# ATUC128D3 device description
Architecture: AVR32_UC3; Family: AVR UC3
Registers are 32-bit, read-write, reset 0x0 unless marked. A register's access mark holds for its fields unless they carry their own. Offsets are from the block's base; [hi:lo] are bit positions; lines under a group give offsets from that group; {n}, {i} and the like mark numbered series; 'fields as' and 'values as' point back to an identical list.

## PWMA — Pulse Width Modulation Controller
Instances: PWMA 0xffff4800
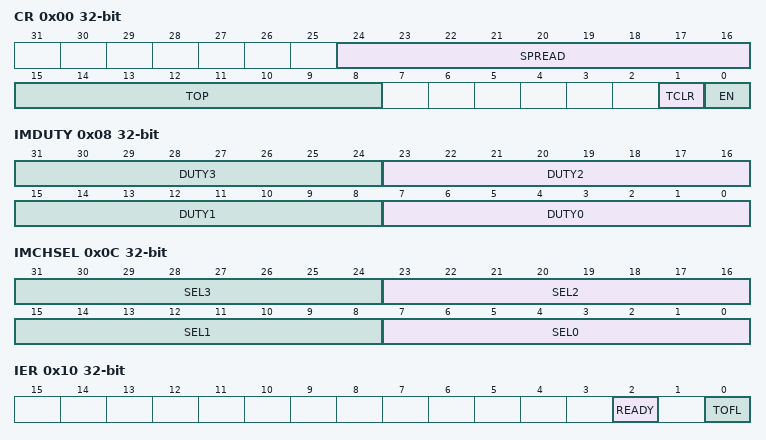
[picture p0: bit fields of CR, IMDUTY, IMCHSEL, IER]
0x00 CR — Control Register
  [24:16] SPREAD — Spread Spectrum Counter Value
  [15:8] TOP — Timebase Counter Top Value
  [1] TCLR — Timebase Clear
  [0] EN — Module enable
0x04 ISDUTY wo — Interlinked Single Value Duty Register
  [11:0] DUTY — Duty Cycle Value
0x08 IMDUTY wo — Interlinked Multiple Value Duty Register
  [8n+7:8n] DUTY{n} (n=0..3) — Duty cycle
0x0C IMCHSEL wo — Interlinked Multiple Value Channel Select
  [8n+7:8n] SEL{n} (n=0..3) — Channel Select {n}
0x10 IER wo — Interrupt Enable Register
  [2] READY — Interface Ready
  [0] TOFL — Timebase Overflow
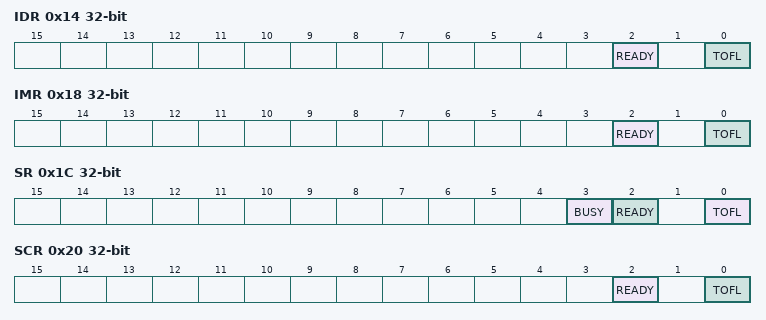
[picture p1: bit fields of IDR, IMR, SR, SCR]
0x14 IDR wo — Interrupt Disable Register
  [2] READY — Interface Ready
  [0] TOFL — Timebase Overflow
0x18 IMR ro — Interrupt Mask Register
  [2] READY — Interface Ready
  [0] TOFL — Timebase Overflow
0x1C SR ro — Status Register
  [3] BUSY — Interface Busy
  [2] READY — Interface Ready
  [0] TOFL — Timebase Overflow
0x20 SCR wo — Status Clear Register
  [2] READY — Interface Ready
  [0] TOFL — Timebase Overflow
0x24 PARAMETER ro reset 0x24
  [7:0] CHANNELS — Channels implemented
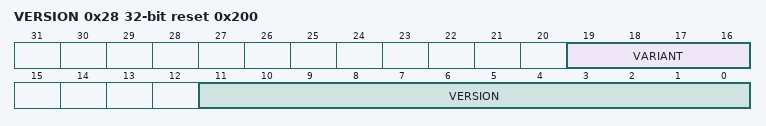
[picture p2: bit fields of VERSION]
0x28 VERSION ro reset 0x200
  [19:16] VARIANT — Variant number
  [11:0] VERSION — Version number
0x2C TVR — Top Value Register
  [11:0] TOP — Timebase Counter Top Value
{0x30+0x10*i} CHGROUP[{i}] (i=0..4) group
  0x00 ISCHSE wo — Interlinked Single Value Channel
    [31:0] SET — Single Value Channel Set
  0x04 CHER — Channel Event Response Register
    [31:0] CHER — Channel Event Response
  0x08 CHEE — Channel Event Enable Register
    [31:0] CHEE — Channel Event Enable
  0x0C CW — Composite Waveform Generator
    [31:0] XOR — Pair Waveform XORed
{0x80+4i} DUTY{i} wo (i=0..3) — Duty Value Register {i}
  [11:0] DUTY — Duty Cycle Value

## TWIM — Two-wire Master Interface
Instances: TWIM 0xffff4000
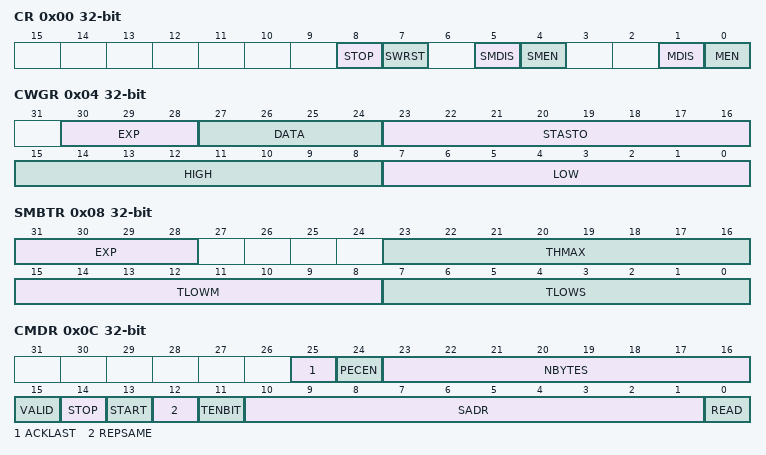
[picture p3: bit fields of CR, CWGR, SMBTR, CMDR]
0x00 CR wo — Control
  [8] STOP — Stop the current transfer
  [7] SWRST — Software Reset
  [5] SMDIS — SMBus Disable
  [4] SMEN — SMBus Enable
  [1] MDIS — Master Disable
  [0] MEN — Master Enable
0x04 CWGR — Clock Waveform Generator
  [30:28] EXP — Clock Prescaler
  [27:24] DATA — Data Setup and Hold Cycles
  [23:16] STASTO — START and STOP Cycles
  [15:8] HIGH — Clock High Cycles
  [7:0] LOW — Clock Low Cycles
0x08 SMBTR — SMBus Timing
  [31:28] EXP — SMBus Timeout Clock prescaler
  [23:16] THMAX — Clock High maximum cycles
  [15:8] TLOWM — Master Clock stretch maximum cycles
  [7:0] TLOWS — Slave Clock stretch maximum cycles
0x0C CMDR — Command
  [25] ACKLAST — ACK Last Master RX Byte
  [24] PECEN — Packet Error Checking Enable
  [23:16] NBYTES — Number of data bytes in transfer
  [15] VALID — CMDR Valid
  [14] STOP — Send STOP condition
  [13] START — Send START condition
  [12] REPSAME — Transfer is to same address as previous address
  [11] TENBIT — Ten Bit Addressing Mode
  [10:1] SADR — Slave Address
  [0] READ — Transfer Direction
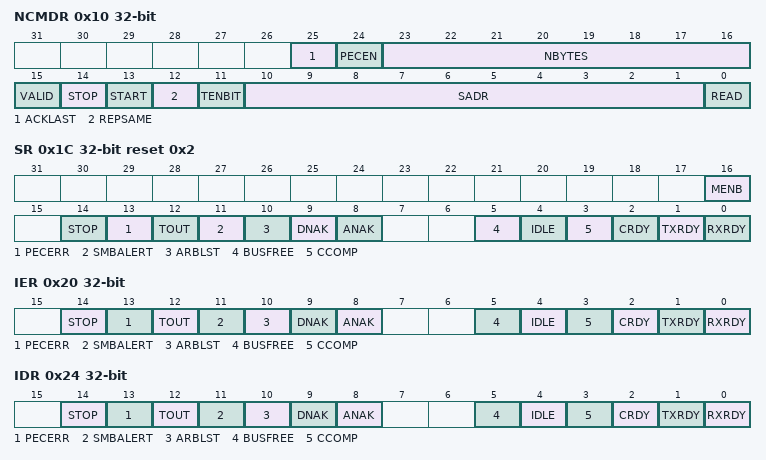
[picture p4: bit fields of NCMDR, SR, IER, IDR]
0x10 NCMDR — Next Command
  fields as CMDR
0x14 RHR ro — Receive Holding
  [7:0] RXDATA — Received Data
0x18 THR wo — Transmit Holding
  [7:0] TXDATA — Data to Transmit
0x1C SR ro reset 0x2 — Status
  [16] MENB — Master Interface Enable
  [14] STOP — Stop Request Accepted
  [13] PECERR — PEC Error
  [12] TOUT — Timeout
  [11] SMBALERT — SMBus Alert
  [10] ARBLST — Arbitration Lost
  [9] DNAK — NAK in Data Phase Received
  [8] ANAK — NAK in Address Phase Received
  [5] BUSFREE — Two-wire Bus is Free
  [4] IDLE — Master Interface is Idle
  [3] CCOMP — Command Complete
  [2] CRDY — Ready for More Commands
  [1] TXRDY — THR Data Ready
  [0] RXRDY — RHR Data Ready
0x20 IER wo — Interrupt Enable Register
  [14] STOP — Stop Request Accepted
  [13] PECERR — PEC Error
  [12] TOUT — Timeout
  [11] SMBALERT — SMBus Alert
  [10] ARBLST — Arbitration Lost
  [9] DNAK — NAK in Data Phase Received
  [8] ANAK — NAK in Address Phase Received
  [5] BUSFREE — Two-wire Bus is Free
  [4] IDLE — Master Interface is Idle
  [3] CCOMP — Command Complete
  [2] CRDY — Ready for More Commands
  [1] TXRDY — THR Data Ready
  [0] RXRDY — RHR Data Ready
0x24 IDR wo — Interrupt Disable Register
  fields as IER
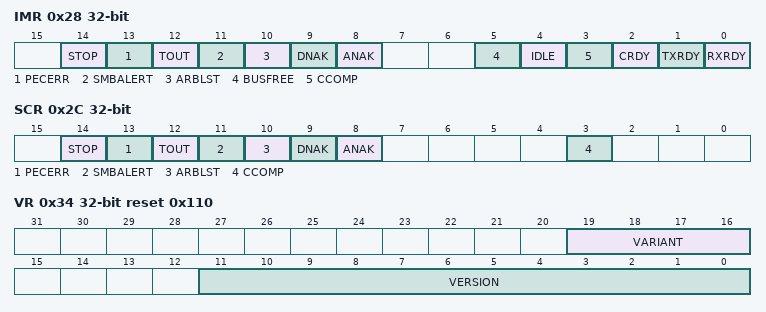
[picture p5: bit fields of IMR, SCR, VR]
0x28 IMR ro — Interrupt Mask Register
  fields as IER
0x2C SCR wo — Status Clear Register
  [14] STOP — Stop Request Accepted
  [13] PECERR — PEC Error
  [12] TOUT — Timeout
  [11] SMBALERT — SMBus Alert
  [10] ARBLST — Arbitration Lost
  [9] DNAK — NAK in Data Phase Received
  [8] ANAK — NAK in Address Phase Received
  [3] CCOMP — Command Complete
0x30 PR ro — Parameter Register
0x34 VR ro reset 0x110 — Version Register
  [19:16] VARIANT — Variant number
  [11:0] VERSION — Version number
